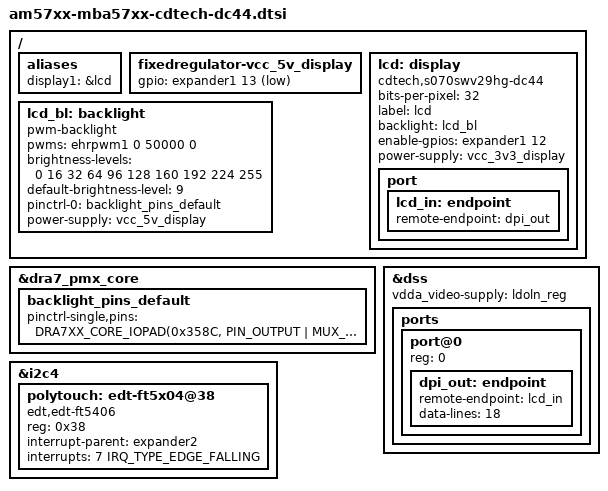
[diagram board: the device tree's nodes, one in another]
// SPDX-License-Identifier: (GPL-2.0+ OR MIT)
/*
 * Device Tree file for TQ AM57xx baseboard MBa57xx.
 *
 * Copyright 2020 TQ-Systems GmbH
 *
 * Author: Michael Krummsdorf <michael.krummsdorf@tq-group.com>
 */

/ {
	aliases {
		display1 = &lcd;
	};

	fixedregulator-vcc_5v_display {
		gpio = <&expander1 13 GPIO_ACTIVE_LOW>;
	};

	lcd: display {
		compatible = "cdtech,s070swv29hg-dc44", "simple-panel";
		bits-per-pixel = <32>; /* 32: RGB888/666 mode */
		label = "lcd";
		backlight = <&lcd_bl>;
		/* lcd power enable LCD_PWR_EN */
		enable-gpios = <&expander1 12 GPIO_ACTIVE_HIGH>;
		power-supply = <&vcc_3v3_display>;
		status = "okay";

		port {
			lcd_in: endpoint {
				remote-endpoint = <&dpi_out>;
			};
		};
	};

	lcd_bl: backlight {
		compatible = "pwm-backlight";
		pwms = <&ehrpwm1 0 50000 0>;
		brightness-levels = <0 16 32 64 96 128 160 192 224 255>;
		default-brightness-level = <9>;
		pinctrl-names = "default";
		pinctrl-0 = <&backlight_pins_default>;
		power-supply = <&vcc_5v_display>;
	};
};

&dra7_pmx_core {
	backlight_pins_default: backlight_pins_default {
		pinctrl-single,pins = <
			DRA7XX_CORE_IOPAD(0x358C, PIN_OUTPUT | MUX_MODE10) /* vin2a_d9.ehrpwm2A */
		>;
	};
};

/* display subsystem */
&dss {
	status = "okay";
	vdda_video-supply = <&ldoln_reg>;

	ports {
		#address-cells = <1>;
		#size-cells = <0>;

		port@0 {
			reg = <0>;
			dpi_out: endpoint {
				remote-endpoint = <&lcd_in>;
				data-lines = <18>;
			};
		};
	};
};

&i2c4 {
	polytouch: edt-ft5x04@38 {
		compatible = "edt,edt-ft5406", "edt,edt-ft5x06";
		reg = <0x38>;
		/* Touch IRQ manually connected to GPIO_EXP_IO7 */
		interrupt-parent = <&expander2>;
		interrupts = <7 IRQ_TYPE_EDGE_FALLING>;
		status = "okay";
	};
};
